# RK3399-AP register map
File version: 1
CPU: CA7 r0p1, little endian, MPU, FPU, I-cache, D-cache, VTOR, 4 interrupt priority bits, 0 interrupts
Registers are 32-bit, read-write, reset 0x0 unless marked. A register's access mark holds for its fields unless they carry their own. Offsets are from the block's base; [hi:lo] are bit positions; {n}, {i} and the like mark numbered series.

## GRF (part 3 of 4)
Base 0xFF770000
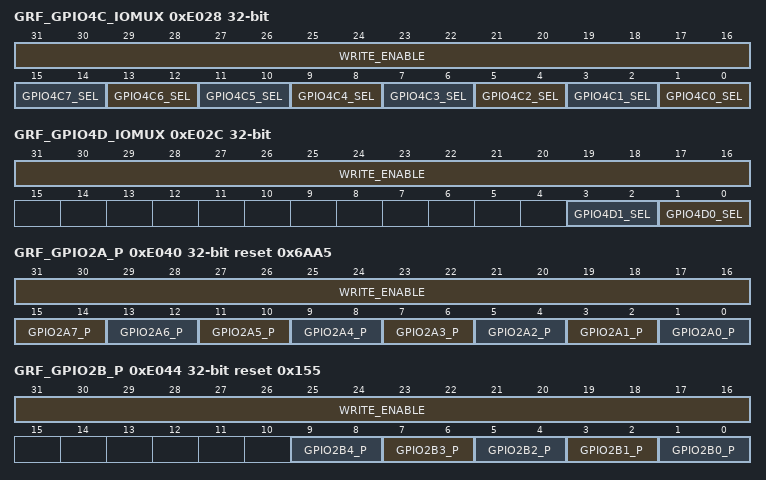
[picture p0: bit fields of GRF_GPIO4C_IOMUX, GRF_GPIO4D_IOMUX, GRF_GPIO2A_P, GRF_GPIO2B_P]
0xE028 GRF_GPIO4C_IOMUX — GPIO4C iomux control
  [31:16] WRITE_ENABLE — bit0~15 write enable When bit 16=1, bit 0 can be written by software . When bit 16=0, bit 0 cannot be written by software; When bit 17=1, bit 1 can be written by software . When bit 17=0, bit 1 cannot be written by software; ...... When bit 31=1, bit 15 can be written by software . When bit 31=0, bit 15 cannot be written by software;
  [15:14] GPIO4C7_SEL — GPIO4C[7] iomux select 2\'b00: gpio 2\'b01: hdmi_cecinout 2\'b10: edp_hotplug 2\'b11: reserved
  [13:12] GPIO4C6_SEL — GPIO4C[6] iomux select 2\'b00: gpio 2\'b01: pwm_1 2\'b10: reserved 2\'b11: reserved
  [11:10] GPIO4C5_SEL — GPIO4C[5] iomux select 2\'b00: gpio 2\'b01: spdif_tx 2\'b10: reserved 2\'b11: reserved
  [9:8] GPIO4C4_SEL — GPIO4C[4] iomux select 2\'b00: gpio 2\'b01: uart2dbgc_sout 2\'b10: uarthdcp_sout 2\'b11: reserved
  [7:6] GPIO4C3_SEL — GPIO4C[3] iomux select 2\'b00: gpio 2\'b01: uart2dbgc_sin 2\'b10: uarthdcp_sin 2\'b11: reserved
  [5:4] GPIO4C2_SEL — GPIO4C[2] iomux select 2\'b00: gpio 2\'b01: pwm_0 2\'b10: vop0_pwm 2\'b11: vop1_pwm
  [3:2] GPIO4C1_SEL — GPIO4C[1] iomux select 2\'b00: gpio 2\'b01: i2c3hdmi_scl 2\'b10: uart2dbgb_sout 2\'b11: hdmii2c_scl
  [1:0] GPIO4C0_SEL — GPIO4C[0] iomux select 2\'b00: gpio 2\'b01: i2c3hdmi_sda 2\'b10: uart2dbgb_sin 2\'b11: hdmii2c_sda
0xE02C GRF_GPIO4D_IOMUX — GPIO4D iomux control
  [31:16] WRITE_ENABLE — bit0~15 write enable When bit 16=1, bit 0 can be written by software . When bit 16=0, bit 0 cannot be written by software; When bit 17=1, bit 1 can be written by software . When bit 17=0, bit 1 cannot be written by software; ...... When bit 31=1, bit 15 can be written by software . When bit 31=0, bit 15 cannot be written by software;
  [3:2] GPIO4D1_SEL — GPIO4D[1] iomux select 2\'b00: gpio 2\'b01: dp_hotplug 2\'b10: reserved 2\'b11: reserved
  [1:0] GPIO4D0_SEL — GPIO4D[0] iomux select 2\'b00: gpio 2\'b01: pcie_clkreqnb 2\'b10: reserved 2\'b11: reserved
0xE040 GRF_GPIO2A_P reset 0x6AA5 — GPIO2A PU/PD control
  [31:16] WRITE_ENABLE — bit0~15 write enable When bit 16=1, bit 0 can be written by software . When bit 16=0, bit 0 cannot be written by software; When bit 17=1, bit 1 can be written by software . When bit 17=0, bit 1 cannot be written by software; ...... When bit 31=1, bit 15 can be written by software . When bit 31=0, bit 15 cannot be written by software;
  [2n+1:2n] GPIO2A{n}_P (n=0..7) — GPIO2A PU/PD programmation section, every GPIO bit corresponding to 2bits 2\'b00: Z(Noraml operaton); 2\'b01: weak 1(pull-up); 2\'b10: weak 0(pull-down); 2\'b11: Repeater(Bus keeper)
0xE044 GRF_GPIO2B_P reset 0x155 — GPIO2B PU/PD control
  [31:16] WRITE_ENABLE — bit0~15 write enable When bit 16=1, bit 0 can be written by software . When bit 16=0, bit 0 cannot be written by software; When bit 17=1, bit 1 can be written by software . When bit 17=0, bit 1 cannot be written by software; ...... When bit 31=1, bit 15 can be written by software . When bit 31=0, bit 15 cannot be written by software;
  [2n+1:2n] GPIO2B{n}_P (n=0..4) — GPIO2B PU/PD programmation section, every GPIO bit corresponding to 2bits 2\'b00: Z(Noraml operaton); 2\'b01: weak 1(pull-up); 2\'b10: weak 0(pull-down); 2\'b11: Repeater(Bus keeper)
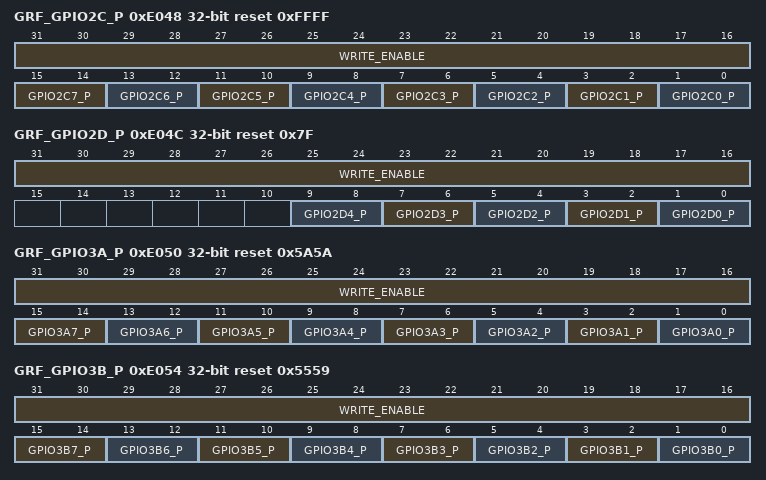
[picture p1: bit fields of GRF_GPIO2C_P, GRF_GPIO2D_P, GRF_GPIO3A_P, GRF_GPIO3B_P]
0xE048 GRF_GPIO2C_P reset 0xFFFF — GPIO2C PU/PD control
  [31:16] WRITE_ENABLE — bit0~15 write enable When bit 16=1, bit 0 can be written by software . When bit 16=0, bit 0 cannot be written by software; When bit 17=1, bit 1 can be written by software . When bit 17=0, bit 1 cannot be written by software; ...... When bit 31=1, bit 15 can be written by software . When bit 31=0, bit 15 cannot be written by software;
  [2n+1:2n] GPIO2C{n}_P (n=0..7) — GPIO2C PE/PS programmation section, every GPIO bit corresponding to 2bits 2\'b00: pervious-state 2\'b01: weak 0(pull-down); 2\'b10: pervious-state 2\'b11: weak 1(pull-up);
0xE04C GRF_GPIO2D_P reset 0x7F — GPIO2D PU/PD control
  [31:16] WRITE_ENABLE — bit0~15 write enable When bit 16=1, bit 0 can be written by software . When bit 16=0, bit 0 cannot be written by software; When bit 17=1, bit 1 can be written by software . When bit 17=0, bit 1 cannot be written by software; ...... When bit 31=1, bit 15 can be written by software . When bit 31=0, bit 15 cannot be written by software;
  [2n+1:2n] GPIO2D{n}_P (n=0..4) — GPIO2D PE/PS programmation section, every GPIO bit corresponding to 2bits 2\'b00: pervious-state 2\'b01: weak 0(pull-down); 2\'b10: pervious-state 2\'b11: weak 1(pull-up);
0xE050 GRF_GPIO3A_P reset 0x5A5A — GPIO3A PU/PD control
  [31:16] WRITE_ENABLE — bit0~15 write enable When bit 16=1, bit 0 can be written by software . When bit 16=0, bit 0 cannot be written by software; When bit 17=1, bit 1 can be written by software . When bit 17=0, bit 1 cannot be written by software; ...... When bit 31=1, bit 15 can be written by software . When bit 31=0, bit 15 cannot be written by software;
  [2n+1:2n] GPIO3A{n}_P (n=0..7) — GPIO3A PU/PD programmation section, every GPIO bit corresponding to 2bits 2\'b00: Z(Noraml operaton); 2\'b01: weak 1(pull-up); 2\'b10: weak 0(pull-down); 2\'b11: Repeater(Bus keeper)
0xE054 GRF_GPIO3B_P reset 0x5559 — GPIO3B PU/PD control
  [31:16] WRITE_ENABLE — bit0~15 write enable When bit 16=1, bit 0 can be written by software . When bit 16=0, bit 0 cannot be written by software; When bit 17=1, bit 1 can be written by software . When bit 17=0, bit 1 cannot be written by software; ...... When bit 31=1, bit 15 can be written by software . When bit 31=0, bit 15 cannot be written by software;
  [2n+1:2n] GPIO3B{n}_P (n=0..7) — GPIO3B PU/PD programmation section, every GPIO bit corresponding to 2bits 2\'b00: Z(Noraml operaton); 2\'b01: weak 1(pull-up); 2\'b10: weak 0(pull-down); 2\'b11: Repeater(Bus keeper)
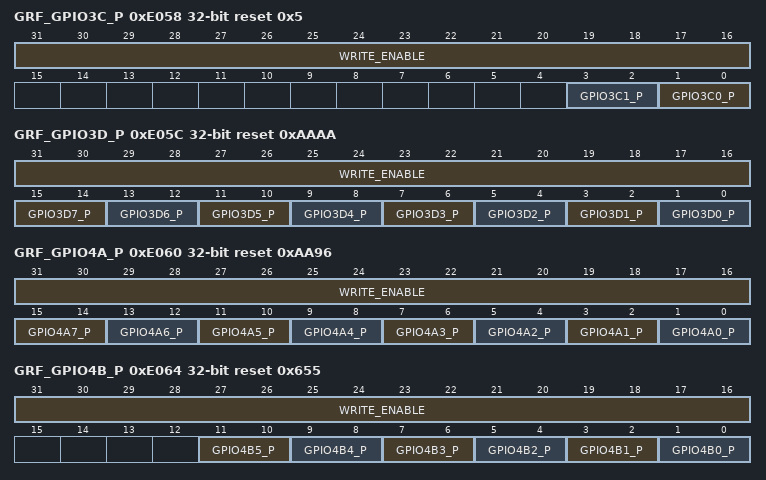
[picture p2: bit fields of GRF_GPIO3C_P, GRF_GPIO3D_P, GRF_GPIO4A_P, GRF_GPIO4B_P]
0xE058 GRF_GPIO3C_P reset 0x5 — GPIO3C PU/PD control
  [31:16] WRITE_ENABLE — bit0~15 write enable When bit 16=1, bit 0 can be written by software . When bit 16=0, bit 0 cannot be written by software; When bit 17=1, bit 1 can be written by software . When bit 17=0, bit 1 cannot be written by software; ...... When bit 31=1, bit 15 can be written by software . When bit 31=0, bit 15 cannot be written by software;
  [3:2] GPIO3C1_P — GPIO3A PU/PD programmation section, every GPIO bit corresponding to 2bits 2\'b00: Z(Noraml operaton); 2\'b01: weak 1(pull-up); 2\'b10: weak 0(pull-down); 2\'b11: Repeater(Bus keeper)
  [1:0] GPIO3C0_P — GPIO3C PU/PD programmation section, every GPIO bit corresponding to 2bits 2\'b00: Z(Noraml operaton); 2\'b01: weak 1(pull-up); 2\'b10: weak 0(pull-down); 2\'b11: Repeater(Bus keeper)
0xE05C GRF_GPIO3D_P reset 0xAAAA — GPIO3D PU/PD control
  [31:16] WRITE_ENABLE — bit0~15 write enable When bit 16=1, bit 0 can be written by software . When bit 16=0, bit 0 cannot be written by software; When bit 17=1, bit 1 can be written by software . When bit 17=0, bit 1 cannot be written by software; ...... When bit 31=1, bit 15 can be written by software . When bit 31=0, bit 15 cannot be written by software;
  [2n+1:2n] GPIO3D{n}_P (n=0..7) — GPIO3D PU/PD programmation section, every GPIO bit corresponding to 2bits 2\'b00: Z(Noraml operaton); 2\'b01: weak 1(pull-up); 2\'b10: weak 0(pull-down); 2\'b11: Repeater(Bus keeper)
0xE060 GRF_GPIO4A_P reset 0xAA96 — GPIO4A PU/PD control
  [31:16] WRITE_ENABLE — bit0~15 write enable When bit 16=1, bit 0 can be written by software . When bit 16=0, bit 0 cannot be written by software; When bit 17=1, bit 1 can be written by software . When bit 17=0, bit 1 cannot be written by software; ...... When bit 31=1, bit 15 can be written by software . When bit 31=0, bit 15 cannot be written by software;
  [2n+1:2n] GPIO4A{n}_P (n=0..7) — GPIO4A PU/PD programmation section, every GPIO bit corresponding to 2bits 2\'b00: Z(Noraml operaton); 2\'b01: weak 1(pull-up); 2\'b10: weak 0(pull-down); 2\'b11: Repeater(Bus keeper)
0xE064 GRF_GPIO4B_P reset 0x655 — GPIO4B PU/PD control
  [31:16] WRITE_ENABLE — bit0~15 write enable When bit 16=1, bit 0 can be written by software . When bit 16=0, bit 0 cannot be written by software; When bit 17=1, bit 1 can be written by software . When bit 17=0, bit 1 cannot be written by software; ...... When bit 31=1, bit 15 can be written by software . When bit 31=0, bit 15 cannot be written by software;
  [2n+1:2n] GPIO4B{n}_P (n=0..5) — GPIO4B PU/PD programmation section, every GPIO bit corresponding to 2bits 2\'b00: Z(Noraml operaton); 2\'b01: weak 1(pull-up); 2\'b10: weak 0(pull-down); 2\'b11: Repeater(Bus keeper)
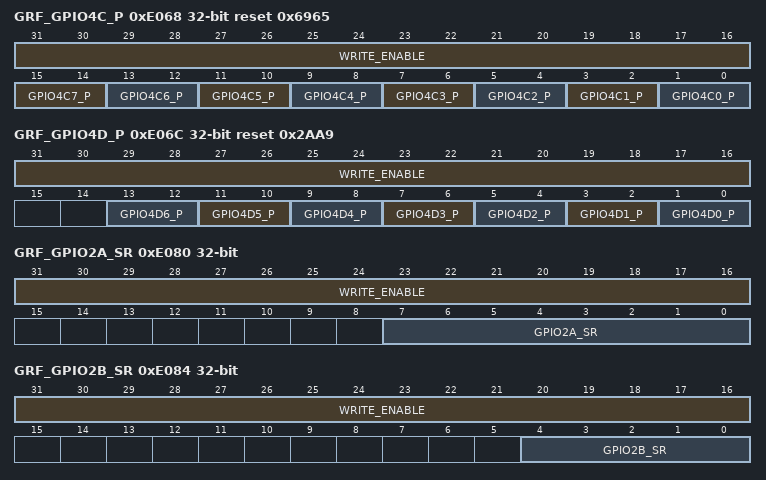
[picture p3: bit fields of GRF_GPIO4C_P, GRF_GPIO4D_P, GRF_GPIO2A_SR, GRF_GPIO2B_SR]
0xE068 GRF_GPIO4C_P reset 0x6965 — GPIO4C PU/PD control
  [31:16] WRITE_ENABLE — bit0~15 write enable When bit 16=1, bit 0 can be written by software . When bit 16=0, bit 0 cannot be written by software; When bit 17=1, bit 1 can be written by software . When bit 17=0, bit 1 cannot be written by software; ...... When bit 31=1, bit 15 can be written by software . When bit 31=0, bit 15 cannot be written by software;
  [2n+1:2n] GPIO4C{n}_P (n=0..7) — GPIO4C PU/PD programmation section, every GPIO bit corresponding to 2bits 2\'b00: Z(Noraml operaton); 2\'b01: weak 1(pull-up); 2\'b10: weak 0(pull-down); 2\'b11: Repeater(Bus keeper)
0xE06C GRF_GPIO4D_P reset 0x2AA9 — GPIO4D PU/PD control
  [31:16] WRITE_ENABLE — bit0~15 write enable When bit 16=1, bit 0 can be written by software . When bit 16=0, bit 0 cannot be written by software; When bit 17=1, bit 1 can be written by software . When bit 17=0, bit 1 cannot be written by software; ...... When bit 31=1, bit 15 can be written by software . When bit 31=0, bit 15 cannot be written by software;
  [2n+1:2n] GPIO4D{n}_P (n=0..6) — GPIO4D PU/PD programmation section, every GPIO bit corresponding to 2bits 2\'b00: Z(Noraml operaton); 2\'b01: weak 1(pull-up); 2\'b10: weak 0(pull-down); 2\'b11: Repeater(Bus keeper)
0xE080 GRF_GPIO2A_SR — GPIO2A slew rate control
  [31:16] WRITE_ENABLE — bit0~15 write enable When bit 16=1, bit 0 can be written by software . When bit 16=0, bit 0 cannot be written by software; When bit 17=1, bit 1 can be written by software . When bit 17=0, bit 1 cannot be written by software; ...... When bit 31=1, bit 15 can be written by software . When bit 31=0, bit 15 cannot be written by software;
  [7:0] GPIO2A_SR — GPIO slew rate programmation section, every GPIO bit corresponding to 1bits 1\'b0: slow 1\'b1: fast
0xE084 GRF_GPIO2B_SR — GPIO2B slew rate control
  [31:16] WRITE_ENABLE — bit0~15 write enable When bit 16=1, bit 0 can be written by software . When bit 16=0, bit 0 cannot be written by software; When bit 17=1, bit 1 can be written by software . When bit 17=0, bit 1 cannot be written by software; ...... When bit 31=1, bit 15 can be written by software . When bit 31=0, bit 15 cannot be written by software;
  [4:0] GPIO2B_SR — GPIO slew rate programmation section, every GPIO bit corresponding to 1bits 1\'b0: slow 1\'b1: fast
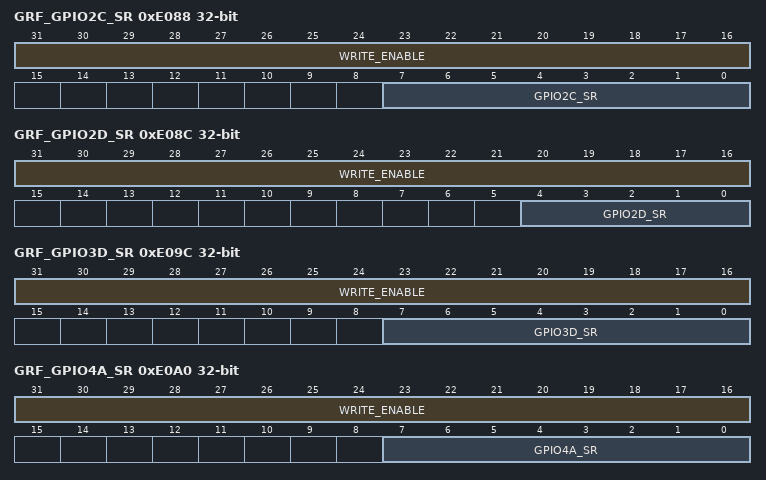
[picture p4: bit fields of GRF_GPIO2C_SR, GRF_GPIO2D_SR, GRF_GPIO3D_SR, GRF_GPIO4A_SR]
0xE088 GRF_GPIO2C_SR — GPIO2C slew rate control
  [31:16] WRITE_ENABLE — bit0~15 write enable When bit 16=1, bit 0 can be written by software . When bit 16=0, bit 0 cannot be written by software; When bit 17=1, bit 1 can be written by software . When bit 17=0, bit 1 cannot be written by software; ...... When bit 31=1, bit 15 can be written by software . When bit 31=0, bit 15 cannot be written by software;
  [7:0] GPIO2C_SR — GPIO slew rate programmation section, every GPIO bit corresponding to 1bits 1\'b0: slow 1\'b1: fast
0xE08C GRF_GPIO2D_SR — GPIO2D slew rate control
  [31:16] WRITE_ENABLE — bit0~15 write enable When bit 16=1, bit 0 can be written by software . When bit 16=0, bit 0 cannot be written by software; When bit 17=1, bit 1 can be written by software . When bit 17=0, bit 1 cannot be written by software; ...... When bit 31=1, bit 15 can be written by software . When bit 31=0, bit 15 cannot be written by software;
  [4:0] GPIO2D_SR — GPIO slew rate programmation section, every GPIO bit corresponding to 1bits 1\'b0: slow 1\'b1: fast
0xE09C GRF_GPIO3D_SR — GPIO3D slew rate control
  [31:16] WRITE_ENABLE — bit0~15 write enable When bit 16=1, bit 0 can be written by software . When bit 16=0, bit 0 cannot be written by software; When bit 17=1, bit 1 can be written by software . When bit 17=0, bit 1 cannot be written by software; ...... When bit 31=1, bit 15 can be written by software . When bit 31=0, bit 15 cannot be written by software;
  [7:0] GPIO3D_SR — GPIO slew rate programmation section, every GPIO bit corresponding to 1bits 1\'b0: slow 1\'b1: fast
0xE0A0 GRF_GPIO4A_SR — GPIO4A slew rate control
  [31:16] WRITE_ENABLE — bit0~15 write enable When bit 16=1, bit 0 can be written by software . When bit 16=0, bit 0 cannot be written by software; When bit 17=1, bit 1 can be written by software . When bit 17=0, bit 1 cannot be written by software; ...... When bit 31=1, bit 15 can be written by software . When bit 31=0, bit 15 cannot be written by software;
  [7:0] GPIO4A_SR — GPIO slew rate programmation section, every GPIO bit corresponding to 1bits 1\'b0: slow 1\'b1: fast
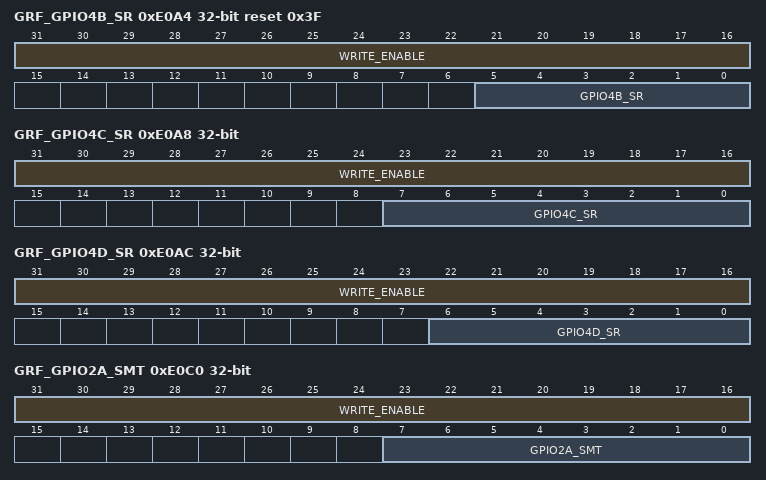
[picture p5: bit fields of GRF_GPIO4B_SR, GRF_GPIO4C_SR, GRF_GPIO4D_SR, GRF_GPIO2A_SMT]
0xE0A4 GRF_GPIO4B_SR reset 0x3F — GPIO4B slew rate control
  [31:16] WRITE_ENABLE — bit0~15 write enable When bit 16=1, bit 0 can be written by software . When bit 16=0, bit 0 cannot be written by software; When bit 17=1, bit 1 can be written by software . When bit 17=0, bit 1 cannot be written by software; ...... When bit 31=1, bit 15 can be written by software . When bit 31=0, bit 15 cannot be written by software;
  [5:0] GPIO4B_SR — GPIO slew rate programmation section, every GPIO bit corresponding to 1bits 1\'b0: slow 1\'b1: fast
0xE0A8 GRF_GPIO4C_SR — GPIO4C slew rate control
  [31:16] WRITE_ENABLE — bit0~15 write enable When bit 16=1, bit 0 can be written by software . When bit 16=0, bit 0 cannot be written by software; When bit 17=1, bit 1 can be written by software . When bit 17=0, bit 1 cannot be written by software; ...... When bit 31=1, bit 15 can be written by software . When bit 31=0, bit 15 cannot be written by software;
  [7:0] GPIO4C_SR — GPIO slew rate programmation section, every GPIO bit corresponding to 1bits 1\'b0: slow 1\'b1: fast
0xE0AC GRF_GPIO4D_SR — GPIO4D slew rate control
  [31:16] WRITE_ENABLE — bit0~15 write enable When bit 16=1, bit 0 can be written by software . When bit 16=0, bit 0 cannot be written by software; When bit 17=1, bit 1 can be written by software . When bit 17=0, bit 1 cannot be written by software; ...... When bit 31=1, bit 15 can be written by software . When bit 31=0, bit 15 cannot be written by software;
  [6:0] GPIO4D_SR — GPIO slew rate programmation section, every GPIO bit corresponding to 1bits 1\'b0: slow 1\'b1: fast
0xE0C0 GRF_GPIO2A_SMT — GPIO2A smitter control register
  [31:16] WRITE_ENABLE — bit0~15 write enable When bit 16=1, bit 0 can be written by software . When bit 16=0, bit 0 cannot be written by software; When bit 17=1, bit 1 can be written by software . When bit 17=0, bit 1 cannot be written by software; ...... When bit 31=1, bit 15 can be written by software . When bit 31=0, bit 15 cannot be written by software;
  [7:0] GPIO2A_SMT — GPIO schmitt trigger control, every GPIO bit corresponding to 1bits . 0: No hysteresis 1: Schmitt trigger enabled.
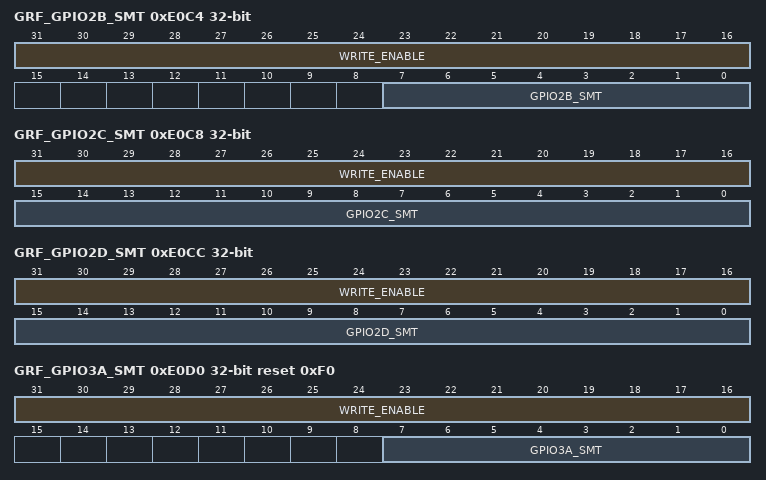
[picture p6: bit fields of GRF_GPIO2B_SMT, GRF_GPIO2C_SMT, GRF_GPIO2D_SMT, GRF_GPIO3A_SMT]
0xE0C4 GRF_GPIO2B_SMT — GPIO2B smitter control register
  [31:16] WRITE_ENABLE — bit0~15 write enable When bit 16=1, bit 0 can be written by software . When bit 16=0, bit 0 cannot be written by software; When bit 17=1, bit 1 can be written by software . When bit 17=0, bit 1 cannot be written by software; ...... When bit 31=1, bit 15 can be written by software . When bit 31=0, bit 15 cannot be written by software;
  [7:0] GPIO2B_SMT — GPIO schmitt trigger control, every GPIO bit corresponding to 1bits . 0: No hysteresis 1: Schmitt trigger enabled.
0xE0C8 GRF_GPIO2C_SMT — GPIO2C smitter control register
  [31:16] WRITE_ENABLE — bit0~15 write enable When bit 16=1, bit 0 can be written by software . When bit 16=0, bit 0 cannot be written by software; When bit 17=1, bit 1 can be written by software . When bit 17=0, bit 1 cannot be written by software; ...... When bit 31=1, bit 15 can be written by software . When bit 31=0, bit 15 cannot be written by software;
  [15:0] GPIO2C_SMT — GPIO schmitt trigger control, every GPIO bit corresponding to 2 bits . 2\'b00: level 0 2\'b01: level 1 2\'b10: level 2 2\'b11: level 3
0xE0CC GRF_GPIO2D_SMT — GPIO2D smitter control register
  [31:16] WRITE_ENABLE — bit0~15 write enable When bit 16=1, bit 0 can be written by software . When bit 16=0, bit 0 cannot be written by software; When bit 17=1, bit 1 can be written by software . When bit 17=0, bit 1 cannot be written by software; ...... When bit 31=1, bit 15 can be written by software . When bit 31=0, bit 15 cannot be written by software;
  [15:0] GPIO2D_SMT — GPIO schmitt trigger control, every GPIO bit corresponding to 2 bits . 2\'b00: level 0 2\'b01: level 1 2\'b10: level 2 2\'b11: level 3
0xE0D0 GRF_GPIO3A_SMT reset 0xF0 — GPIO3A smitter control register
  [31:16] WRITE_ENABLE — bit0~15 write enable When bit 16=1, bit 0 can be written by software . When bit 16=0, bit 0 cannot be written by software; When bit 17=1, bit 1 can be written by software . When bit 17=0, bit 1 cannot be written by software; ...... When bit 31=1, bit 15 can be written by software . When bit 31=0, bit 15 cannot be written by software;
  [7:0] GPIO3A_SMT — GPIO schmitt trigger control, every GPIO bit corresponding to 1bits . 0: No hysteresis 1: Schmitt trigger enabled.
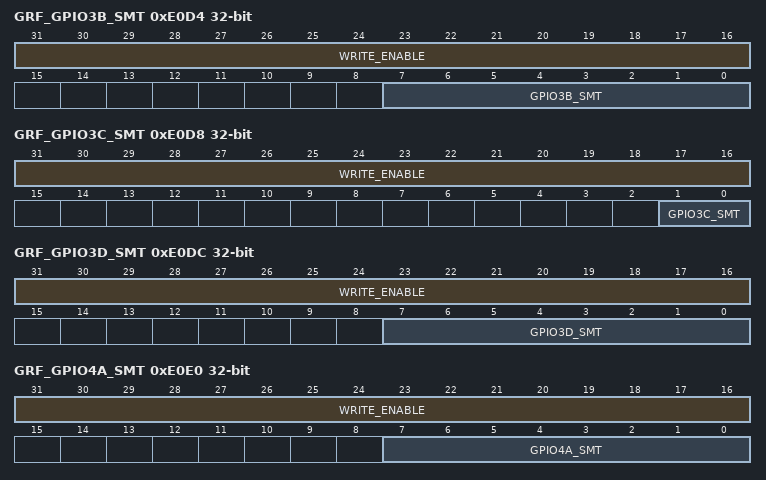
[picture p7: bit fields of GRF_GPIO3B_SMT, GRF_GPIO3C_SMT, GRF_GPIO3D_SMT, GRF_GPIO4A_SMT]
0xE0D4 GRF_GPIO3B_SMT — GPIO3B smitter control register
  [31:16] WRITE_ENABLE — bit0~15 write enable When bit 16=1, bit 0 can be written by software . When bit 16=0, bit 0 cannot be written by software; When bit 17=1, bit 1 can be written by software . When bit 17=0, bit 1 cannot be written by software; ...... When bit 31=1, bit 15 can be written by software . When bit 31=0, bit 15 cannot be written by software;
  [7:0] GPIO3B_SMT — GPIO schmitt trigger control, every GPIO bit corresponding to 1bits . 0: No hysteresis 1: Schmitt trigger enabled.
0xE0D8 GRF_GPIO3C_SMT — GPIO3C smitter control register
  [31:16] WRITE_ENABLE — bit0~15 write enable When bit 16=1, bit 0 can be written by software . When bit 16=0, bit 0 cannot be written by software; When bit 17=1, bit 1 can be written by software . When bit 17=0, bit 1 cannot be written by software; ...... When bit 31=1, bit 15 can be written by software . When bit 31=0, bit 15 cannot be written by software;
  [1:0] GPIO3C_SMT — GPIO schmitt trigger control, every GPIO bit corresponding to 1bits . 0: No hysteresis 1: Schmitt trigger enabled.
0xE0DC GRF_GPIO3D_SMT — GPIO3D smitter control register
  [31:16] WRITE_ENABLE — bit0~15 write enable When bit 16=1, bit 0 can be written by software . When bit 16=0, bit 0 cannot be written by software; When bit 17=1, bit 1 can be written by software . When bit 17=0, bit 1 cannot be written by software; ...... When bit 31=1, bit 15 can be written by software . When bit 31=0, bit 15 cannot be written by software;
  [7:0] GPIO3D_SMT — GPIO schmitt trigger control, every GPIO bit corresponding to 1bits . 0: No hysteresis 1: Schmitt trigger enabled.
0xE0E0 GRF_GPIO4A_SMT — GPIO4A smitter control register
  [31:16] WRITE_ENABLE — bit0~15 write enable When bit 16=1, bit 0 can be written by software . When bit 16=0, bit 0 cannot be written by software; When bit 17=1, bit 1 can be written by software . When bit 17=0, bit 1 cannot be written by software; ...... When bit 31=1, bit 15 can be written by software . When bit 31=0, bit 15 cannot be written by software;
  [7:0] GPIO4A_SMT — GPIO schmitt trigger control, every GPIO bit corresponding to 1bits . 0: No hysteresis 1: Schmitt trigger enabled.
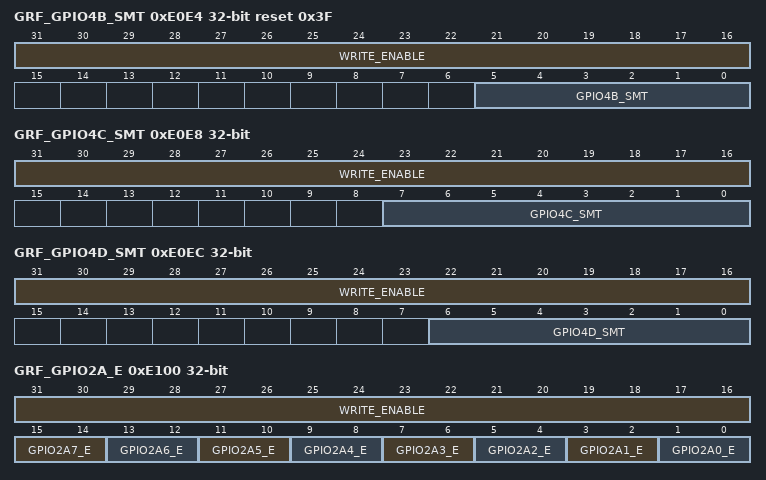
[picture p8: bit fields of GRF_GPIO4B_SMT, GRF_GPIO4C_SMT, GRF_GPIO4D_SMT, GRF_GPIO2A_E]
0xE0E4 GRF_GPIO4B_SMT reset 0x3F — GPIO4B smitter control register
  [31:16] WRITE_ENABLE — bit0~15 write enable When bit 16=1, bit 0 can be written by software . When bit 16=0, bit 0 cannot be written by software; When bit 17=1, bit 1 can be written by software . When bit 17=0, bit 1 cannot be written by software; ...... When bit 31=1, bit 15 can be written by software . When bit 31=0, bit 15 cannot be written by software;
  [5:0] GPIO4B_SMT — GPIO schmitt trigger control, every GPIO bit corresponding to 1bits . 0: No hysteresis 1: Schmitt trigger enabled.
0xE0E8 GRF_GPIO4C_SMT — GPIO4C smitter control register
  [31:16] WRITE_ENABLE — bit0~15 write enable When bit 16=1, bit 0 can be written by software . When bit 16=0, bit 0 cannot be written by software; When bit 17=1, bit 1 can be written by software . When bit 17=0, bit 1 cannot be written by software; ...... When bit 31=1, bit 15 can be written by software . When bit 31=0, bit 15 cannot be written by software;
  [7:0] GPIO4C_SMT — GPIO schmitt trigger control, every GPIO bit corresponding to 1bits . 0: No hysteresis 1: Schmitt trigger enabled.
0xE0EC GRF_GPIO4D_SMT — GPIO4D smitter control register
  [31:16] WRITE_ENABLE — bit0~15 write enable When bit 16=1, bit 0 can be written by software . When bit 16=0, bit 0 cannot be written by software; When bit 17=1, bit 1 can be written by software . When bit 17=0, bit 1 cannot be written by software; ...... When bit 31=1, bit 15 can be written by software . When bit 31=0, bit 15 cannot be written by software;
  [6:0] GPIO4D_SMT — GPIO schmitt trigger control, every GPIO bit corresponding to 1bits . 0: No hysteresis 1: Schmitt trigger enabled.
0xE100 GRF_GPIO2A_E — GPIO2A drive strength control
  [31:16] WRITE_ENABLE — bit0~15 write enable When bit 16=1, bit 0 can be written by software . When bit 16=0, bit 0 cannot be written by software; When bit 17=1, bit 1 can be written by software . When bit 17=0, bit 1 cannot be written by software; ...... When bit 31=1, bit 15 can be written by software . When bit 31=0, bit 15 cannot be written by software;
  [2n+1:2n] GPIO2A{n}_E (n=0..7) — GPIO2A{n} drive strength control, every GPIO bit corresponding to 2bits 2\'b00: level 0 2\'b01: level 1 2\'b10: level 2 2\'b11: level 3
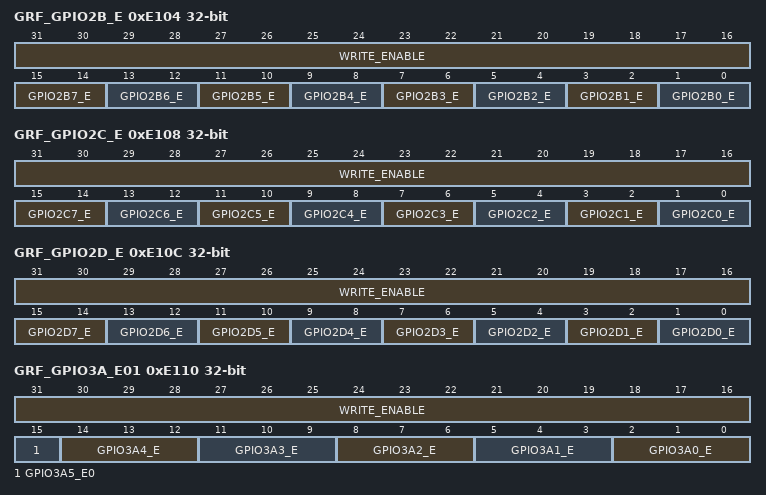
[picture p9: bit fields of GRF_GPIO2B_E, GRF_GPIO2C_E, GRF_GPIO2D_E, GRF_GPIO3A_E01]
0xE104 GRF_GPIO2B_E — GPIO2B drive strength control
  [31:16] WRITE_ENABLE — bit0~15 write enable When bit 16=1, bit 0 can be written by software . When bit 16=0, bit 0 cannot be written by software; When bit 17=1, bit 1 can be written by software . When bit 17=0, bit 1 cannot be written by software; ...... When bit 31=1, bit 15 can be written by software . When bit 31=0, bit 15 cannot be written by software;
  [2n+1:2n] GPIO2B{n}_E (n=0..7) — GPIO2B{n} drive strength control, every GPIO bit corresponding to 2bits 2\'b00: level 0 2\'b01: level 1 2\'b10: level 2 2\'b11: level 3
0xE108 GRF_GPIO2C_E — GPIO2C drive strength control
  [31:16] WRITE_ENABLE — bit0~15 write enable When bit 16=1, bit 0 can be written by software . When bit 16=0, bit 0 cannot be written by software; When bit 17=1, bit 1 can be written by software . When bit 17=0, bit 1 cannot be written by software; ...... When bit 31=1, bit 15 can be written by software . When bit 31=0, bit 15 cannot be written by software;
  [2n+1:2n] GPIO2C{n}_E (n=0..7) — GPIO2C{n} drive strength control, every GPIO bit corresponding to 2bits 2\'b00: level 0 2\'b01: level 1 2\'b10: level 2 2\'b11: level 3
0xE10C GRF_GPIO2D_E — GPIO2D drive strength control
  [31:16] WRITE_ENABLE — bit0~15 write enable When bit 16=1, bit 0 can be written by software . When bit 16=0, bit 0 cannot be written by software; When bit 17=1, bit 1 can be written by software . When bit 17=0, bit 1 cannot be written by software; ...... When bit 31=1, bit 15 can be written by software . When bit 31=0, bit 15 cannot be written by software;
  [2n+1:2n] GPIO2D{n}_E (n=0..7) — GPIO2D{n} drive strength control, every GPIO bit corresponding to 2bits 2\'b00: level 0 2\'b01: level 1 2\'b10: level 2 2\'b11: level 3
0xE110 GRF_GPIO3A_E01 — GPIO3A drive strength control
  [31:16] WRITE_ENABLE — bit0~15 write enable When bit 16=1, bit 0 can be written by software . When bit 16=0, bit 0 cannot be written by software; When bit 17=1, bit 1 can be written by software . When bit 17=0, bit 1 cannot be written by software; ...... When bit 31=1, bit 15 can be written by software . When bit 31=0, bit 15 cannot be written by software;
  [15] GPIO3A5_E0 — GPIO3A5 drive strength control bit0
  [3n+2:3n] GPIO3A{n}_E (n=0..4) — GPIO3A{n} drive strength control bit0 to bit2
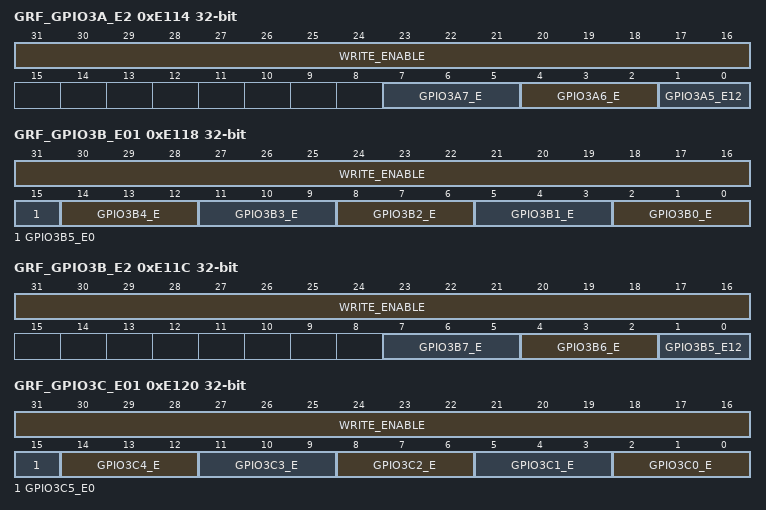
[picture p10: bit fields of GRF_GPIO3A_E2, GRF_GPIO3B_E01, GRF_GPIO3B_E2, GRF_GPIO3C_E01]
0xE114 GRF_GPIO3A_E2 — GPIO3B drive strength control
  [31:16] WRITE_ENABLE — bit0~15 write enable When bit 16=1, bit 0 can be written by software . When bit 16=0, bit 0 cannot be written by software; When bit 17=1, bit 1 can be written by software . When bit 17=0, bit 1 cannot be written by software; ...... When bit 31=1, bit 15 can be written by software . When bit 31=0, bit 15 cannot be written by software;
  [7:5] GPIO3A7_E — GPIO3A7 drive strength control bit0 to bit2
  [4:2] GPIO3A6_E — GPIO3A6 drive strength control bit0 to bit2
  [1:0] GPIO3A5_E12 — GPIO3A5 drive strength control bit1 and bit2
0xE118 GRF_GPIO3B_E01 — GPIO3B drive strength control
  [31:16] WRITE_ENABLE — bit0~15 write enable When bit 16=1, bit 0 can be written by software . When bit 16=0, bit 0 cannot be written by software; When bit 17=1, bit 1 can be written by software . When bit 17=0, bit 1 cannot be written by software; ...... When bit 31=1, bit 15 can be written by software . When bit 31=0, bit 15 cannot be written by software;
  [15] GPIO3B5_E0 — GPIO3B5 drive strength control bit0
  [3n+2:3n] GPIO3B{n}_E (n=0..4) — GPIO3B{n} drive strength control bit0 to bit2
0xE11C GRF_GPIO3B_E2 — GPIO3B drive strength control
  [31:16] WRITE_ENABLE — bit0~15 write enable When bit 16=1, bit 0 can be written by software . When bit 16=0, bit 0 cannot be written by software; When bit 17=1, bit 1 can be written by software . When bit 17=0, bit 1 cannot be written by software; ...... When bit 31=1, bit 15 can be written by software . When bit 31=0, bit 15 cannot be written by software;
  [7:5] GPIO3B7_E — GPIO3B7 drive strength control bit0 to bit2
  [4:2] GPIO3B6_E — GPIO3B6 drive strength control bit0 to bit2
  [1:0] GPIO3B5_E12 — GPIO3B5 drive strength control bit1 to bit2
0xE120 GRF_GPIO3C_E01 — GPIO3C drive strength control
  [31:16] WRITE_ENABLE — bit0~15 write enable When bit 16=1, bit 0 can be written by software . When bit 16=0, bit 0 cannot be written by software; When bit 17=1, bit 1 can be written by software . When bit 17=0, bit 1 cannot be written by software; ...... When bit 31=1, bit 15 can be written by software . When bit 31=0, bit 15 cannot be written by software;
  [15] GPIO3C5_E0 — GPIO3C5 drive strength control bit0
  [3n+2:3n] GPIO3C{n}_E (n=0..4) — GPIO3C{n} drive strength control bit0 to bit2
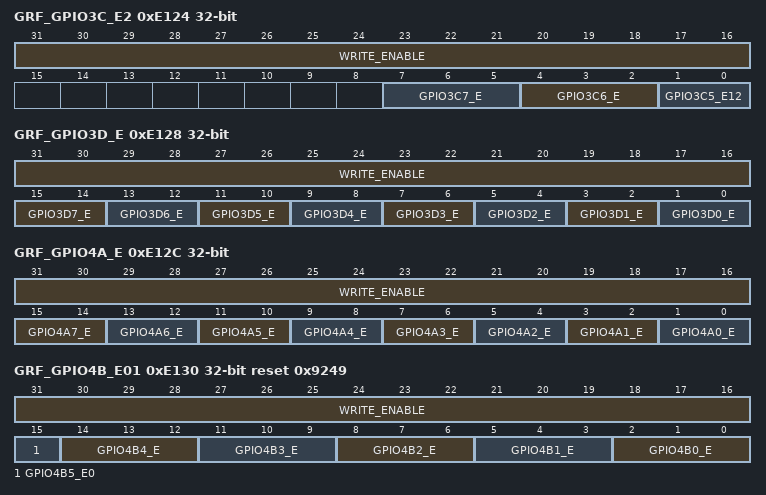
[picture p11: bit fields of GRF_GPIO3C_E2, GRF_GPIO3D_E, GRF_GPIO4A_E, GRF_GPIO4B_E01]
0xE124 GRF_GPIO3C_E2 — GPIO3C drive strength control
  [31:16] WRITE_ENABLE — bit0~15 write enable When bit 16=1, bit 0 can be written by software . When bit 16=0, bit 0 cannot be written by software; When bit 17=1, bit 1 can be written by software . When bit 17=0, bit 1 cannot be written by software; ...... When bit 31=1, bit 15 can be written by software . When bit 31=0, bit 15 cannot be written by software;
  [7:5] GPIO3C7_E — GPIO3C7 drive strength control bit0 to bit2
  [4:2] GPIO3C6_E — GPIO3C6 drive strength control bit0 to bit2
  [1:0] GPIO3C5_E12 — GPIO3C5 drive strength control bit1 and bit2
0xE128 GRF_GPIO3D_E — GPIO3D drive strength control
  [31:16] WRITE_ENABLE — bit0~15 write enable When bit 16=1, bit 0 can be written by software . When bit 16=0, bit 0 cannot be written by software; When bit 17=1, bit 1 can be written by software . When bit 17=0, bit 1 cannot be written by software; ...... When bit 31=1, bit 15 can be written by software . When bit 31=0, bit 15 cannot be written by software;
  [2n+1:2n] GPIO3D{n}_E (n=0..7) — GPIO3D{n} drive strength control, every GPIO bit corresponding to 2bits 2\'b00: level 0 2\'b01: level 1 2\'b10: level 2 2\'b11: level 3
0xE12C GRF_GPIO4A_E — GPIO4A drive strength control
  [31:16] WRITE_ENABLE — bit0~15 write enable When bit 16=1, bit 0 can be written by software . When bit 16=0, bit 0 cannot be written by software; When bit 17=1, bit 1 can be written by software . When bit 17=0, bit 1 cannot be written by software; ...... When bit 31=1, bit 15 can be written by software . When bit 31=0, bit 15 cannot be written by software;
  [2n+1:2n] GPIO4A{n}_E (n=0..7) — GPIO4A{n} drive strength control, every GPIO bit corresponding to 2bits 2\'b00: level 0 2\'b01: level 1 2\'b10: level 2 2\'b11: level 3
0xE130 GRF_GPIO4B_E01 reset 0x9249 — GPIO4B drive strength control
  [31:16] WRITE_ENABLE — bit0~15 write enable When bit 16=1, bit 0 can be written by software . When bit 16=0, bit 0 cannot be written by software; When bit 17=1, bit 1 can be written by software . When bit 17=0, bit 1 cannot be written by software; ...... When bit 31=1, bit 15 can be written by software . When bit 31=0, bit 15 cannot be written by software;
  [15] GPIO4B5_E0 — GPIO4B5 drive strength control bit0
  [3n+2:3n] GPIO4B{n}_E (n=0..4) — GPIO4B{n} drive strength control bit0 to bit2
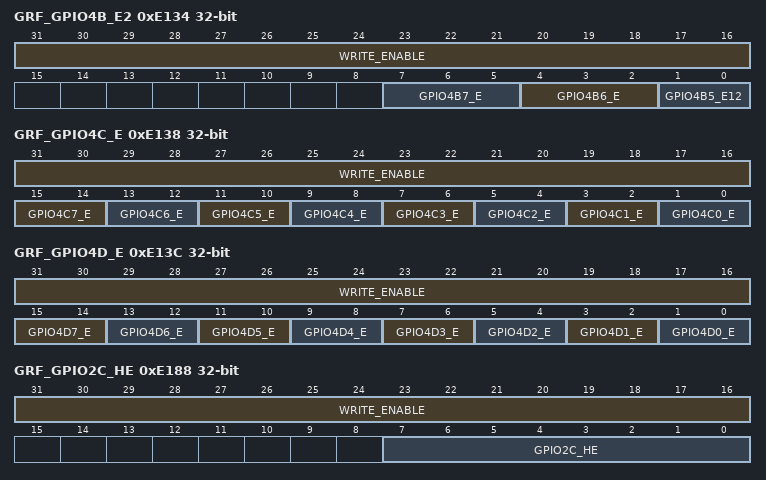
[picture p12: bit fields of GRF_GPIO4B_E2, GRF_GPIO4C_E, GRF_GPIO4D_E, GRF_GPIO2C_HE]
0xE134 GRF_GPIO4B_E2 — GPIO4B drive strength control
  [31:16] WRITE_ENABLE — bit0~15 write enable When bit 16=1, bit 0 can be written by software . When bit 16=0, bit 0 cannot be written by software; When bit 17=1, bit 1 can be written by software . When bit 17=0, bit 1 cannot be written by software; ...... When bit 31=1, bit 15 can be written by software . When bit 31=0, bit 15 cannot be written by software;
  [7:5] GPIO4B7_E — GPIO4B7 drive strength control bit0 to bit2
  [4:2] GPIO4B6_E — GPIO4B6 drive strength control bit0 to bit2
  [1:0] GPIO4B5_E12 — GPIO4B5 drive strength control bit2
0xE138 GRF_GPIO4C_E — GPIO4C drive strength control
  [31:16] WRITE_ENABLE — bit0~15 write enable When bit 16=1, bit 0 can be written by software . When bit 16=0, bit 0 cannot be written by software; When bit 17=1, bit 1 can be written by software . When bit 17=0, bit 1 cannot be written by software; ...... When bit 31=1, bit 15 can be written by software . When bit 31=0, bit 15 cannot be written by software;
  [2n+1:2n] GPIO4C{n}_E (n=0..7) — GPIO4C{n} drive strength control, every GPIO bit corresponding to 2bits 2\'b00: level 0 2\'b01: level 1 2\'b10: level 2 2\'b11: level 3
0xE13C GRF_GPIO4D_E — GPIO4D drive strength control
  [31:16] WRITE_ENABLE — bit0~15 write enable When bit 16=1, bit 0 can be written by software . When bit 16=0, bit 0 cannot be written by software; When bit 17=1, bit 1 can be written by software . When bit 17=0, bit 1 cannot be written by software; ...... When bit 31=1, bit 15 can be written by software . When bit 31=0, bit 15 cannot be written by software;
  [2n+1:2n] GPIO4D{n}_E (n=0..7) — GPIO4D{n} drive strength control, every GPIO bit corresponding to 2bits 2\'b00: level 0 2\'b01: level 1 2\'b10: level 2 2\'b11: level 3
0xE188 GRF_GPIO2C_HE — GPIO2C HE control
  [31:16] WRITE_ENABLE — bit0~15 write enable When bit 16=1, bit 0 can be written by software . When bit 16=0, bit 0 cannot be written by software; When bit 17=1, bit 1 can be written by software . When bit 17=0, bit 1 cannot be written by software; ...... When bit 31=1, bit 15 can be written by software . When bit 31=0, bit 15 cannot be written by software;
  [7:0] GPIO2C_HE — GPIO2C gpio keep privous state control, every GPIO bit corresponding to 1bit 1\'b0: disable 1\'b1: enable
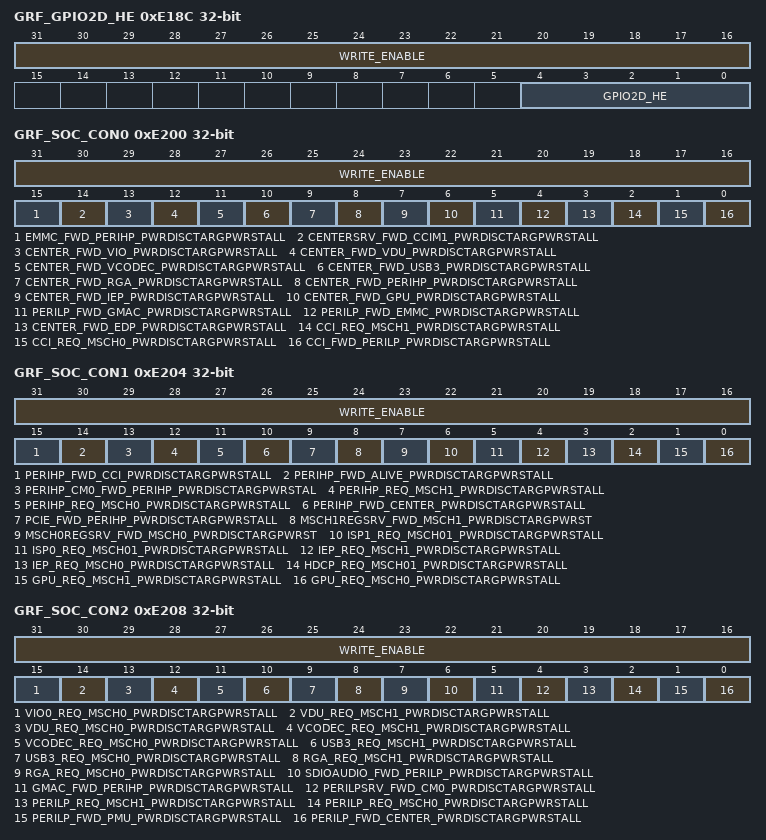
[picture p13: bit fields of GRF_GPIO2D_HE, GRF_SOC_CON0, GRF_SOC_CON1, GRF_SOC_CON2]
0xE18C GRF_GPIO2D_HE — GPIO2D HE control
  [31:16] WRITE_ENABLE — bit0~15 write enable When bit 16=1, bit 0 can be written by software . When bit 16=0, bit 0 cannot be written by software; When bit 17=1, bit 1 can be written by software . When bit 17=0, bit 1 cannot be written by software; ...... When bit 31=1, bit 15 can be written by software . When bit 31=0, bit 15 cannot be written by software;
  [4:0] GPIO2D_HE — GPIO2D gpio keep privous state control, every GPIO bit corresponding to 1bit 1\'b0: disable 1\'b1: enable
0xE200 GRF_SOC_CON0 — SoC control register 0
  [31:16] WRITE_ENABLE — bit0~15 write enable When bit 16=1, bit 0 can be written by software . When bit 16=0, bit 0 cannot be written by software; When bit 17=1, bit 1 can be written by software . When bit 17=0, bit 1 cannot be written by software; ...... When bit 31=1, bit 15 can be written by software . When bit 31=0, bit 15 cannot be written by software;
  [15] EMMC_FWD_PERIHP_PWRDISCTARGPWRSTALL — noc_emmc_fwd_perihp_rsp_err_stall bit control 0: error response 1: stall response
  [14] CENTERSRV_FWD_CCIM1_PWRDISCTARGPWRSTALL — noc_centersrv_fwd_ccim1_rsp_err_stall bit control 0: error response 1: stall response
  [13] CENTER_FWD_VIO_PWRDISCTARGPWRSTALL — noc_center_fwd_vio_rsp_err_stall bit control 0: error response 1: stall response
  [12] CENTER_FWD_VDU_PWRDISCTARGPWRSTALL — noc_center_fwd_vdu_rsp_err_stall bit control 0: error response 1: stall response
  [11] CENTER_FWD_VCODEC_PWRDISCTARGPWRSTALL — noc_center_fwd_vcodec_rsp_err_stall bit control 0: error response 1: stall response
  [10] CENTER_FWD_USB3_PWRDISCTARGPWRSTALL — noc_center_fwd_usb3_rsp_err_stall bit control 0: error response 1: stall response
  [9] CENTER_FWD_RGA_PWRDISCTARGPWRSTALL — noc_center_fwd_rga_rsp_err_stall bit control 0: error response 1: stall response
  [8] CENTER_FWD_PERIHP_PWRDISCTARGPWRSTALL — noc_center_fwd_perihp_rsp_err_stall bit control 0: error response 1: stall response
  [7] CENTER_FWD_IEP_PWRDISCTARGPWRSTALL — noc_center_fwd_iep_rsp_err_stall bit control 0: error response 1: stall response
  [6] CENTER_FWD_GPU_PWRDISCTARGPWRSTALL — noc_center_fwd_gpu_rsp_err_stall bit control 0: error response 1: stall response
  [5] PERILP_FWD_GMAC_PWRDISCTARGPWRSTALL — perilp_fwd_gmac_rsp_err_stall bit control 0: error response 1: stall response
  [4] PERILP_FWD_EMMC_PWRDISCTARGPWRSTALL — perilp_fwd_emmc_rsp_err_stall bit control 0: error response 1: stall response
  [3] CENTER_FWD_EDP_PWRDISCTARGPWRSTALL — noc_center_fwd_edp_rsp_err_stall bit control 0: error response 1: stall response
  [2] CCI_REQ_MSCH1_PWRDISCTARGPWRSTALL — noc_cci_req_msch1_rsp_err_stall bit control 0: error response 1: stall response
  [1] CCI_REQ_MSCH0_PWRDISCTARGPWRSTALL — noc__rsp_err_stall bit control 0: error response 1: stall response
  [0] CCI_FWD_PERILP_PWRDISCTARGPWRSTALL — noc_cci_fwd_perilp_rsp_err_stall bit control 0: error response 1: stall response
0xE204 GRF_SOC_CON1 — SoC control register 2
  [31:16] WRITE_ENABLE — bit0~15 write enable When bit 16=1, bit 0 can be written by software . When bit 16=0, bit 0 cannot be written by software; When bit 17=1, bit 1 can be written by software . When bit 17=0, bit 1 cannot be written by software; ...... When bit 31=1, bit 15 can be written by software . When bit 31=0, bit 15 cannot be written by software;
  [15] PERIHP_FWD_CCI_PWRDISCTARGPWRSTALL — noc_perihp_fwd_cci_rsp_err_stall bit control 0: error response 1: stall response
  [14] PERIHP_FWD_ALIVE_PWRDISCTARGPWRSTALL — noc_perihp_fwd_alive_rsp_err_stall bit control 0: error response 1: stall response
  [13] PERIHP_CM0_FWD_PERIHP_PWRDISCTARGPWRSTAL — l noc_perihp_cm0_fwd_perihp_rsp_err_stall bit control 0: error response 1: stall response
  [12] PERIHP_REQ_MSCH1_PWRDISCTARGPWRSTALL — noc_perihp_req_msch1_rsp_err_stall bit control 0: error response 1: stall response
  [11] PERIHP_REQ_MSCH0_PWRDISCTARGPWRSTALL — noc_perihp_req_msch0_rsp_err_stall bit control 0: error response 1: stall response
  [10] PERIHP_FWD_CENTER_PWRDISCTARGPWRSTALL — noc_perihp_fwd_center_rsp_err_stall bit control 0: error response 1: stall response
  [9] PCIE_FWD_PERIHP_PWRDISCTARGPWRSTALL — noc_pcie_fwd_perihp_rsp_err_stall bit control 0: error response 1: stall response
  [8] MSCH1REGSRV_FWD_MSCH1_PWRDISCTARGPWRST — all noc_msch1regsrv_fwd_msch1_rsp_err_stall bit control 0: error response 1: stall response
  [7] MSCH0REGSRV_FWD_MSCH0_PWRDISCTARGPWRST — all noc_msch0regsrv_fwd_msch0_rsp_err_stall bit control 0: error response 1: stall response
  [6] ISP1_REQ_MSCH01_PWRDISCTARGPWRSTALL — noc_isp1_req_msch01_rsp_err_stall bit control 0: error response 1: stall response
  [5] ISP0_REQ_MSCH01_PWRDISCTARGPWRSTALL — noc_isp0_req_msch01_rsp_err_stall bit control 0: error response 1: stall response
  [4] IEP_REQ_MSCH1_PWRDISCTARGPWRSTALL — noc_iep_req_msch1_rsp_err_stall bit control 0: error response 1: stall response
  [3] IEP_REQ_MSCH0_PWRDISCTARGPWRSTALL — noc_iep_req_msch0_rsp_err_stall bit control 0: error response 1: stall response
  [2] HDCP_REQ_MSCH01_PWRDISCTARGPWRSTALL — noc_hdcp_req_msch01_rsp_err_stall bit control 0: error response 1: stall response
  [1] GPU_REQ_MSCH1_PWRDISCTARGPWRSTALL — noc_gpu_req_msch1_rsp_err_stall bit control 0: error response 1: stall response
  [0] GPU_REQ_MSCH0_PWRDISCTARGPWRSTALL — noc_gpu_req_msch0_rsp_err_stall bit control 0: error response 1: stall response
0xE208 GRF_SOC_CON2 — SoC control register 1
  [31:16] WRITE_ENABLE — Fbit0~15 write enable When bit 16=1, bit 0 can be written by software . When bit 16=0, bit 0 cannot be written by software; When bit 17=1, bit 1 can be written by software . When bit 17=0, bit 1 cannot be written by software; ...... When bit 31=1, bit 15 can be written by software . When bit 31=0, bit 15 cannot be written by software;
  [15] VIO0_REQ_MSCH0_PWRDISCTARGPWRSTALL — noc_vio0_req_msch0_rsp_err_stall bit control 0: error response 1: stall response
  [14] VDU_REQ_MSCH1_PWRDISCTARGPWRSTALL — noc_vdu_req_msch1_rsp_err_stall bit control 0: error response 1: stall response
  [13] VDU_REQ_MSCH0_PWRDISCTARGPWRSTALL — noc_vdu_req_msch0_rsp_err_stall bit control 0: error response 1: stall response
  [12] VCODEC_REQ_MSCH1_PWRDISCTARGPWRSTALL — noc_vcodec_req_msch1_rsp_err_stall bit control 0: error response 1: stall response
  [11] VCODEC_REQ_MSCH0_PWRDISCTARGPWRSTALL — noc_vcodec_req_msch0_rsp_err_stall bit control 0: error response 1: stall response
  [10] USB3_REQ_MSCH1_PWRDISCTARGPWRSTALL — noc_usb3_req_msch1_rsp_err_stall bit control 0: error response 1: stall response
  [9] USB3_REQ_MSCH0_PWRDISCTARGPWRSTALL — noc_usb3_req_msch0_rsp_err_stall bit control 0: error response 1: stall response
  [8] RGA_REQ_MSCH1_PWRDISCTARGPWRSTALL — noc_rga_req_msch1_rsp_err_stall bit control 0: error response 1: stall response
  [7] RGA_REQ_MSCH0_PWRDISCTARGPWRSTALL — noc_rga_req_msch0_rsp_err_stall bit control 0: error response 1: stall response
  [6] SDIOAUDIO_FWD_PERILP_PWRDISCTARGPWRSTALL — noc_pmu_fwd_perilp_rsp_err_stall bit control 0: error response 1: stall response
  [5] GMAC_FWD_PERIHP_PWRDISCTARGPWRSTALL — noc_gmac_fwd_perihp_rsp_err_stall bit control 0: error response 1: stall response
  [4] PERILPSRV_FWD_CM0_PWRDISCTARGPWRSTALL — noc_perilpsrv_fwd_cm0_rsp_err_stall bit control 0: error response 1: stall response
  [3] PERILP_REQ_MSCH1_PWRDISCTARGPWRSTALL — noc_perilp_req_msch1_rsp_err_stall bit control 0: error response 1: stall response
  [2] PERILP_REQ_MSCH0_PWRDISCTARGPWRSTALL — noc_perilp_req_msch0_rsp_err_stall bit control 0: error response 1: stall response
  [1] PERILP_FWD_PMU_PWRDISCTARGPWRSTALL — noc_perilp_fwd_pmu_rsp_err_stall bit control 0: error response 1: stall response
  [0] PERILP_FWD_CENTER_PWRDISCTARGPWRSTALL — noc_perilp_fwd_center_rsp_err_stall bit control 0: error response 1: stall response
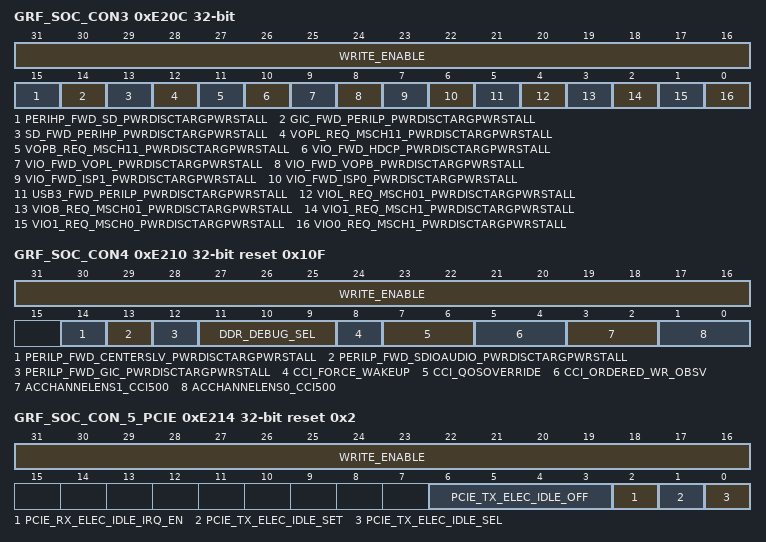
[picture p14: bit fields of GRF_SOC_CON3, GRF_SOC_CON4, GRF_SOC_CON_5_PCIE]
0xE20C GRF_SOC_CON3 — SoC control register 3
  [31:16] WRITE_ENABLE — bit0~15 write enable When bit 16=1, bit 0 can be written by software . When bit 16=0, bit 0 cannot be written by software; When bit 17=1, bit 1 can be written by software . When bit 17=0, bit 1 cannot be written by software; ...... When bit 31=1, bit 15 can be written by software . When bit 31=0, bit 15 cannot be written by software;
  [15] PERIHP_FWD_SD_PWRDISCTARGPWRSTALL — noc_perihp_fwd_sd_rsp_err_stall bit control 0: error response 1: stall response
  [14] GIC_FWD_PERILP_PWRDISCTARGPWRSTALL — noc_gic_fwd_perilp_rsp_err_stall bit control 0: error response 1: stall response
  [13] SD_FWD_PERIHP_PWRDISCTARGPWRSTALL — noc_sd_fwd_perihp_rsp_err_stall bit control 0: error response 1: stall response
  [12] VOPL_REQ_MSCH11_PWRDISCTARGPWRSTALL — noc_vopl_req_msch11_rsp_err_stall bit control 0: error response 1: stall response
  [11] VOPB_REQ_MSCH11_PWRDISCTARGPWRSTALL — noc_vopb_req_msch11_rsp_err_stall bit control 0: error response 1: stall response
  [10] VIO_FWD_HDCP_PWRDISCTARGPWRSTALL — noc_vio_fwd_hdcp_rsp_err_stall bit control 0: error response 1: stall response
  [9] VIO_FWD_VOPL_PWRDISCTARGPWRSTALL — noc_vio_fwd_vopl_rsp_err_stall bit control 0: error response 1: stall response
  [8] VIO_FWD_VOPB_PWRDISCTARGPWRSTALL — noc_vio_fwd_vopb_rsp_err_stall bit control 0: error response 1: stall response
  [7] VIO_FWD_ISP1_PWRDISCTARGPWRSTALL — noc_vio_fwd_isp1_rsp_err_stall bit control 0: error response 1: stall response
  [6] VIO_FWD_ISP0_PWRDISCTARGPWRSTALL — noc_vio_fwd_isp0_rsp_err_stall bit control 0: error response 1: stall response
  [5] USB3_FWD_PERILP_PWRDISCTARGPWRSTALL — noc_usb3_fwd_perilp_rsp_err_stall bit control 0: error response 1: stall response
  [4] VIOL_REQ_MSCH01_PWRDISCTARGPWRSTALL — noc_viol_req_msch01_rsp_err_stall bit control 0: error response 1: stall response
  [3] VIOB_REQ_MSCH01_PWRDISCTARGPWRSTALL — noc_viob_req_msch01_rsp_err_stall bit control 0: error response 1: stall response
  [2] VIO1_REQ_MSCH1_PWRDISCTARGPWRSTALL — noc_vio1_req_msch1_rsp_err_stall bit control 0: error response 1: stall response
  [1] VIO1_REQ_MSCH0_PWRDISCTARGPWRSTALL — noc_vio1_req_msch0_rsp_err_stall bit control 0: error response 1: stall response
  [0] VIO0_REQ_MSCH1_PWRDISCTARGPWRSTALL — noc_vio0_req_msch1_rsp_err_stall bit control 0: error response 1: stall response
0xE210 GRF_SOC_CON4 reset 0x10F — SoC control register 4
  [31:16] WRITE_ENABLE — bit0~15 write enable When bit 16=1, bit 0 can be written by software . When bit 16=0, bit 0 cannot be written by software; When bit 17=1, bit 1 can be written by software . When bit 17=0, bit 1 cannot be written by software; ...... When bit 31=1, bit 15 can be written by software . When bit 31=0, bit 15 cannot be written by software;
  [14] PERILP_FWD_CENTERSLV_PWRDISCTARGPWRSTALL — noc_perilp_fwd_centerslv_rsp_err_stall bit control 0: error response 1: stall response
  [13] PERILP_FWD_SDIOAUDIO_PWRDISCTARGPWRSTALL — noc_perilp_fwd_sdioaudio_rsp_err_stall bit control 0: error response 1: stall response
  [12] PERILP_FWD_GIC_PWRDISCTARGPWRSTALL — noc_perilp_fwd_gic_rsp_err_stall bit control 0: error response 1: stall response
  [11:9] DDR_DEBUG_SEL — select ddr debug port 0: ddr_dbug_port[7:0] 1: ddr_dbug_port[15:8] 2: ddr_dbug_port[23:16] 3: ddr_dbug_port[31:24] 4: ddr_dbug_port[39:32] 5: ddr_dbug_port[47:40] 6: ddr_dbug_port[55:48] 7: ddr_dbug_port[63:56]
  [8] CCI_FORCE_WAKEUP — cci force wakeup control 1\'b0: disable 1\'b1: enable
  [7:6] CCI_QOSOVERRIDE — cci port QOSOVERRIDE bit control
  [5:4] CCI_ORDERED_WR_OBSV — cci port ORDERED_WRITE_OBSERVATION control
  [3:2] ACCHANNELENS1_CCI500 — CCI ACCHANNELEN input control. Slave interface supports DVM messages. This is overridden to 0x0 if you set the Control Override Register[1].
  [1:0] ACCHANNELENS0_CCI500 — CCI ACCHANNELEN input control. Slave interface supports DVM messages. This is overridden to 0x0 if you set the Control Override Register[1].
0xE214 GRF_SOC_CON_5_PCIE reset 0x2 — SoC control register 5
  [31:16] WRITE_ENABLE — bit0~15 write enable When bit 16=1, bit 0 can be written by software . When bit 16=0, bit 0 cannot be written by software; When bit 17=1, bit 1 can be written by software . When bit 17=0, bit 1 cannot be written by software; ...... When bit 31=1, bit 15 can be written by software . When bit 31=0, bit 15 cannot be written by software;
  [6:3] PCIE_TX_ELEC_IDLE_OFF — pcie_tx_elec_idle_off[3:0] port control
  [2] PCIE_RX_ELEC_IDLE_IRQ_EN — pcie_rx_elec_idle_irq_en port control
  [1] PCIE_TX_ELEC_IDLE_SET — pcie_tx_elec_idle_set port control
  [0] PCIE_TX_ELEC_IDLE_SEL — pcie_tx_elec_idle_sel port control
